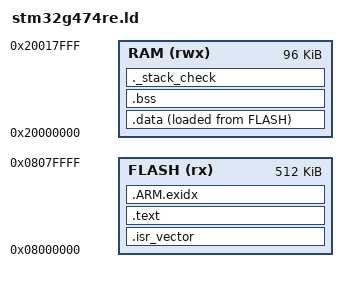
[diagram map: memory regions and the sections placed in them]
/* STM32G474RE: 512 KB flash, SRAM1 (80 KB) + SRAM2 (16 KB) contiguous. */
ENTRY(Reset_Handler)

MEMORY
{
  FLASH (rx)  : ORIGIN = 0x08000000, LENGTH = 512K
  RAM   (rwx) : ORIGIN = 0x20000000, LENGTH = 96K
}

_estack = ORIGIN(RAM) + LENGTH(RAM);

SECTIONS
{
  .isr_vector :
  {
    . = ALIGN(4);
    KEEP(*(.isr_vector))
    . = ALIGN(4);
  } > FLASH

  .text :
  {
    . = ALIGN(4);
    *(.text*)
    *(.rodata*)
    *(.glue_7) *(.glue_7t)
    KEEP(*(.init)) KEEP(*(.fini))
    . = ALIGN(4);
  } > FLASH

  .ARM.exidx : { *(.ARM.exidx*) } > FLASH

  _sidata = LOADADDR(.data);

  .data :
  {
    . = ALIGN(4);
    _sdata = .;
    *(.data*)
    . = ALIGN(4);
    _edata = .;
  } > RAM AT > FLASH

  .bss (NOLOAD) :
  {
    . = ALIGN(4);
    _sbss = .;
    *(.bss*)
    *(COMMON)
    . = ALIGN(4);
    _ebss = .;
  } > RAM

  /* At least 4 KB left for the stack. */
  ._stack_check (NOLOAD) :
  {
    . = ALIGN(8);
    . = . + 4K;
  } > RAM
}
